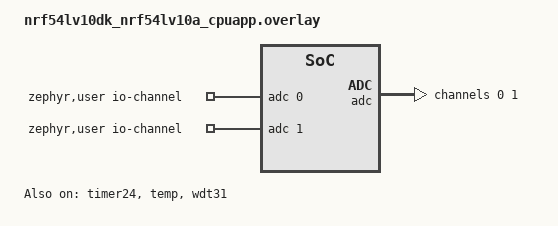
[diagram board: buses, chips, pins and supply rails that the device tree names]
/*
 * Copyright (c) 2025 Nordic Semiconductor ASA
 *
 * SPDX-License-Identifier: LicenseRef-Nordic-5-Clause
 */

/ {
	aliases {
		led2 = &led2;
		test-counter = &timer24;
	};

	zephyr,user {
		io-channels = <&adc 0>, <&adc 1>;
	};
};

&adc {
	status = "okay";
	#address-cells = <1>;
	#size-cells = <0>;

	channel@0 {
		reg = <0>;
		zephyr,gain = "ADC_GAIN_1";
		zephyr,reference = "ADC_REF_INTERNAL";
		zephyr,acquisition-time = <ADC_ACQ_TIME(ADC_ACQ_TIME_MICROSECONDS, 10)>;
		zephyr,input-positive = <NRF_SAADC_AIN4>; /* P1.07 */
		zephyr,resolution = <10>;
	};

	channel@1 {
		reg = <1>;
		zephyr,gain = "ADC_GAIN_1";
		zephyr,reference = "ADC_REF_INTERNAL";
		zephyr,acquisition-time = <ADC_ACQ_TIME_DEFAULT>;
		zephyr,input-positive = <NRF_SAADC_AIN5>; /* P1.05 */
		zephyr,resolution = <12>;
	};
};

&timer24 {
	status = "okay";
	prescaler = <4>;
};

temp_sensor: &temp {
	status = "okay";
};

&wdt31 {
	status = "okay";
};
